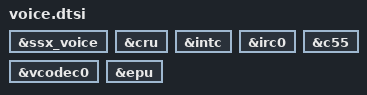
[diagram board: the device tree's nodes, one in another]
// SPDX-License-Identifier: GPL-2.0
/*
 * Copyright (C) 2024 MaxLinear, Inc.
 */

/******************************************************************************
 ** Board configuration: Voice subsystem settings
 ******************************************************************************/

&ssx_voice {
	status = "okay";
};

&cru {
	status = "okay";
};

&intc {
	status = "okay";
};

&irc0 { /* vcodec0 irq */
	status = "okay";
};

&c55 {
	status = "okay";
};

&vcodec0 {
	status = "okay";
};

&epu {
	/* epu voice is not supported with pd_voice enabled*/
	/delete-node/ pd_voice@LGM_EPU_PD_VOICE;
};
